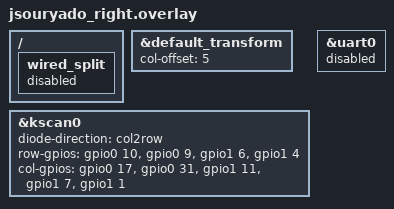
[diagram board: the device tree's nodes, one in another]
/*
 * Copyright (c) 2020 Pete Johanson
 *
 * SPDX-License-Identifier: MIT
 */

#include "jsouryado.dtsi"

&default_transform {
    col-offset = <5>;
};

&kscan0 {
    diode-direction = "col2row";
    row-gpios = <&gpio0 10 (GPIO_ACTIVE_HIGH | GPIO_PULL_DOWN)>,
                <&gpio0 9 (GPIO_ACTIVE_HIGH | GPIO_PULL_DOWN)>,
                <&gpio1 6 (GPIO_ACTIVE_HIGH | GPIO_PULL_DOWN)>,
                <&gpio1 4 (GPIO_ACTIVE_HIGH | GPIO_PULL_DOWN)>;

    col-gpios = <&gpio0 17 GPIO_ACTIVE_HIGH>,
                <&gpio0 31 GPIO_ACTIVE_HIGH>,
                <&gpio1 11 GPIO_ACTIVE_HIGH>,
                <&gpio1 7 GPIO_ACTIVE_HIGH>,
                <&gpio1 1 GPIO_ACTIVE_HIGH>;
};

/ {
    wired_split {
        // compatible = "zmk,wired-split";
        // device = <&uart0>;
        status = "disabled";
    };
};

/* make sure the hardware UART exists */
&uart0 {
    // status = "okay";
    // current-speed = <115200>;
    status = "disabled";
};
